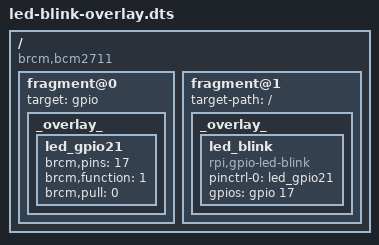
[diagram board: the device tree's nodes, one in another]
/dts-v1/;
/plugin/;

/ {
    compatible = "brcm,bcm2711";

    fragment@0 {
        target = <&gpio>;
        _overlay_ {
            led_gpio21: led_gpio21 {
                brcm,pins = <17>;
                brcm,function = <1>;      // output
                brcm,pull = <0>;          // no pull
            };
        };
    };

    fragment@1 {
        target-path = "/";
        _overlay_ {
            led_blink {
                compatible = "rpi,gpio-led-blink";
                pinctrl-names = "default";
                pinctrl-0 = <&led_gpio21>;
                gpios = <&gpio 17 0>;
            };
        };
    };
};
